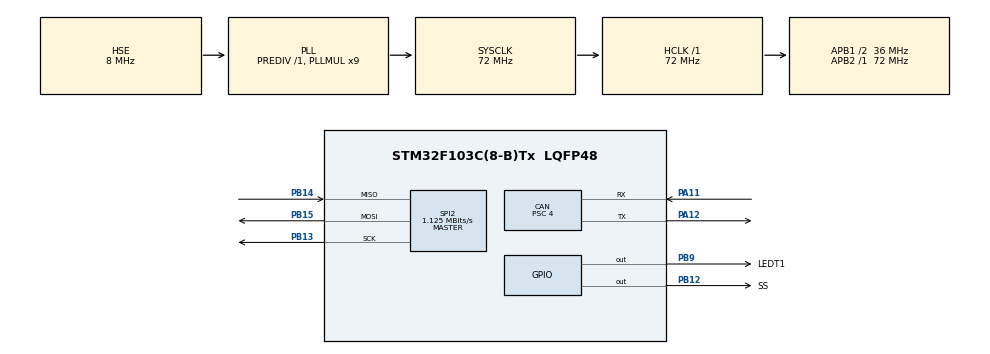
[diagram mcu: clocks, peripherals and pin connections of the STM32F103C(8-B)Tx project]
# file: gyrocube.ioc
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CAN.BS1=CAN_BS1_5TQ
CAN.BS2=CAN_BS2_3TQ
CAN.CalculateBaudRate=1000000
CAN.CalculateTimeBit=1000
CAN.CalculateTimeQuantum=111.11111111111111
CAN.Prescaler=4
FREERTOS.Tasks01=defaultTask,0,128,StartDefaultTask,Default,NULL,Dynamic,NULL,NULL
Mcu.Family=STM32F1
Mcu.Name=STM32F103C(8-B)Tx
Mcu.Package=LQFP48
NVIC.PriorityGroup=NVIC_PRIORITYGROUP_4
NVIC.TIM1_UP_IRQn=true\:15\:0\:false\:false\:true\:false\:false\:true\:true
NVIC.TimeBase=TIM1_UP_IRQn
NVIC.TimeBaseIP=TIM1
NVIC.USB_LP_CAN1_RX0_IRQn=true\:6\:0\:true\:false\:true\:true\:true\:true\:true
PA11.Mode=CAN_Activate
PA11.Signal=CAN_RX
PA12.Mode=CAN_Activate
PA12.Signal=CAN_TX
PA13.Mode=Serial_Wire
PA13.Signal=SYS_JTMS-SWDIO
PA14.Mode=Serial_Wire
PA14.Signal=SYS_JTCK-SWCLK
PB12.GPIO_Label=SS
PB12.Signal=GPIO_Output
PB13.Mode=Full_Duplex_Master
PB13.Signal=SPI2_SCK
PB14.Mode=Full_Duplex_Master
PB14.Signal=SPI2_MISO
PB15.Mode=Full_Duplex_Master
PB15.Signal=SPI2_MOSI
PB9.GPIO_Label=LEDT1
PB9.Signal=GPIO_Output
PD0-OSC_IN.Mode=HSE-External-Oscillator
PD0-OSC_IN.Signal=RCC_OSC_IN
PD1-OSC_OUT.Mode=HSE-External-Oscillator
PD1-OSC_OUT.Signal=RCC_OSC_OUT
ProjectManager.HeapSize=0x200
ProjectManager.StackSize=0x400
ProjectManager.TargetToolchain=Makefile
RCC.AHBFreq_Value=72000000
RCC.APB1CLKDivider=RCC_HCLK_DIV2
RCC.APB1Freq_Value=36000000
RCC.APB1TimFreq_Value=72000000
RCC.APB2Freq_Value=72000000
RCC.APB2TimFreq_Value=72000000
RCC.HCLKFreq_Value=72000000
RCC.PLLMUL=RCC_PLL_MUL9
RCC.PLLSourceVirtual=RCC_PLLSOURCE_HSE
RCC.SYSCLKFreq_VALUE=72000000
RCC.SYSCLKSource=RCC_SYSCLKSOURCE_PLLCLK
RCC.USBFreq_Value=72000000
SPI2.BaudRatePrescaler=SPI_BAUDRATEPRESCALER_32
SPI2.CalculateBaudRate=1.125 MBits/s
SPI2.Direction=SPI_DIRECTION_2LINES
SPI2.Mode=SPI_MODE_MASTER
SPI2.VirtualType=VM_MASTER
VP_FREERTOS_VS_CMSIS_V1.Mode=CMSIS_V1
VP_SYS_VS_tim1.Mode=TIM1
board=custom

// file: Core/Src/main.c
/* USER CODE BEGIN Header */
/**
  ******************************************************************************
  * @file           : main.c
  * @brief          : Main program body
  ******************************************************************************
  * @attention
  *
  * Copyright (c) 2025 STMicroelectronics.
  * All rights reserved.
  *
  * This software is licensed under terms that can be found in the LICENSE file
  * in the root directory of this software component.
  * If no LICENSE file comes with this software, it is provided AS-IS.
  *
  ******************************************************************************
  */
/* USER CODE END Header */
#include "main.h"
#include "cmsis_os.h"

CAN_HandleTypeDef hcan;

SPI_HandleTypeDef hspi2;

osThreadId defaultTaskHandle;

void SystemClock_Config(void);
static void MX_GPIO_Init(void);
static void MX_CAN_Init(void);
static void MX_SPI2_Init(void);
void StartDefaultTask(void const * argument);

int main(void)
{

  /* MCU Configuration--------------------------------------------------------*/

  /* Reset of all peripherals, Initializes the Flash interface and the Systick. */
  HAL_Init();

  /* Configure the system clock */
  SystemClock_Config();

  /* Initialize all configured peripherals */
  MX_GPIO_Init();
  MX_CAN_Init();
  MX_SPI2_Init();

  /* Create the thread(s) */
  /* definition and creation of defaultTask */
  osThreadDef(defaultTask, StartDefaultTask, osPriorityNormal, 0, 128);
  defaultTaskHandle = osThreadCreate(osThread(defaultTask), NULL);

  /* Start scheduler */
  osKernelStart();

  /* We should never get here as control is now taken by the scheduler */

  /* Infinite loop */
  while (1)
  {

  }
}

void SystemClock_Config(void)
{
  RCC_OscInitTypeDef RCC_OscInitStruct = {0};
  RCC_ClkInitTypeDef RCC_ClkInitStruct = {0};

  /** Initializes the RCC Oscillators according to the specified parameters
  * in the RCC_OscInitTypeDef structure.
  */
  RCC_OscInitStruct.OscillatorType = RCC_OSCILLATORTYPE_HSE;
  RCC_OscInitStruct.HSEState = RCC_HSE_ON;
  RCC_OscInitStruct.HSEPredivValue = RCC_HSE_PREDIV_DIV1;
  RCC_OscInitStruct.HSIState = RCC_HSI_ON;
  RCC_OscInitStruct.PLL.PLLState = RCC_PLL_ON;
  RCC_OscInitStruct.PLL.PLLSource = RCC_PLLSOURCE_HSE;
  RCC_OscInitStruct.PLL.PLLMUL = RCC_PLL_MUL9;
  if (HAL_RCC_OscConfig(&RCC_OscInitStruct) != HAL_OK)
  {
    Error_Handler();
  }

  /** Initializes the CPU, AHB and APB buses clocks
  */
  RCC_ClkInitStruct.ClockType = RCC_CLOCKTYPE_HCLK|RCC_CLOCKTYPE_SYSCLK
                              |RCC_CLOCKTYPE_PCLK1|RCC_CLOCKTYPE_PCLK2;
  RCC_ClkInitStruct.SYSCLKSource = RCC_SYSCLKSOURCE_PLLCLK;
  RCC_ClkInitStruct.AHBCLKDivider = RCC_SYSCLK_DIV1;
  RCC_ClkInitStruct.APB1CLKDivider = RCC_HCLK_DIV2;
  RCC_ClkInitStruct.APB2CLKDivider = RCC_HCLK_DIV1;

  if (HAL_RCC_ClockConfig(&RCC_ClkInitStruct, FLASH_LATENCY_2) != HAL_OK)
  {
    Error_Handler();
  }
}

static void MX_CAN_Init(void)
{

  hcan.Instance = CAN1;
  hcan.Init.Prescaler = 4;
  hcan.Init.Mode = CAN_MODE_NORMAL;
  hcan.Init.SyncJumpWidth = CAN_SJW_1TQ;
  hcan.Init.TimeSeg1 = CAN_BS1_5TQ;
  hcan.Init.TimeSeg2 = CAN_BS2_3TQ;
  hcan.Init.TimeTriggeredMode = DISABLE;
  hcan.Init.AutoBusOff = DISABLE;
  hcan.Init.AutoWakeUp = DISABLE;
  hcan.Init.AutoRetransmission = DISABLE;
  hcan.Init.ReceiveFifoLocked = DISABLE;
  hcan.Init.TransmitFifoPriority = DISABLE;
  if (HAL_CAN_Init(&hcan) != HAL_OK)
  {
    Error_Handler();
  }

}

static void MX_SPI2_Init(void)
{

  /* SPI2 parameter configuration*/
  hspi2.Instance = SPI2;
  hspi2.Init.Mode = SPI_MODE_MASTER;
  hspi2.Init.Direction = SPI_DIRECTION_2LINES;
  hspi2.Init.DataSize = SPI_DATASIZE_8BIT;
  hspi2.Init.CLKPolarity = SPI_POLARITY_LOW;
  hspi2.Init.CLKPhase = SPI_PHASE_1EDGE;
  hspi2.Init.NSS = SPI_NSS_SOFT;
  hspi2.Init.BaudRatePrescaler = SPI_BAUDRATEPRESCALER_32;
  hspi2.Init.FirstBit = SPI_FIRSTBIT_MSB;
  hspi2.Init.TIMode = SPI_TIMODE_DISABLE;
  hspi2.Init.CRCCalculation = SPI_CRCCALCULATION_DISABLE;
  hspi2.Init.CRCPolynomial = 10;
  if (HAL_SPI_Init(&hspi2) != HAL_OK)
  {
    Error_Handler();
  }

}

static void MX_GPIO_Init(void)
{
  GPIO_InitTypeDef GPIO_InitStruct = {0};

  /* GPIO Ports Clock Enable */
  __HAL_RCC_GPIOD_CLK_ENABLE();
  __HAL_RCC_GPIOB_CLK_ENABLE();
  __HAL_RCC_GPIOA_CLK_ENABLE();

  /*Configure GPIO pin Output Level */
  HAL_GPIO_WritePin(GPIOB, SS_Pin|LEDT1_Pin, GPIO_PIN_RESET);

  /*Configure GPIO pins : SS_Pin LEDT1_Pin */
  GPIO_InitStruct.Pin = SS_Pin|LEDT1_Pin;
  GPIO_InitStruct.Mode = GPIO_MODE_OUTPUT_PP;
  GPIO_InitStruct.Pull = GPIO_NOPULL;
  GPIO_InitStruct.Speed = GPIO_SPEED_FREQ_LOW;
  HAL_GPIO_Init(GPIOB, &GPIO_InitStruct);

}

void StartDefaultTask(void const * argument)
{
  /* USER CODE BEGIN 5 */
  /* Infinite loop */
  extern void board_main();
  board_main();
  for(;;)
  {

  }
  /* USER CODE END 5 */
}

void HAL_TIM_PeriodElapsedCallback(TIM_HandleTypeDef *htim)
{
  if (htim->Instance == TIM1)
  {
    HAL_IncTick();
  }
}

void Error_Handler(void)
{
  __disable_irq();
  while (1)
  {
  }
}
